# M3351 register map
File version: 1.0
Registers are 32-bit, read-write, reset 0x0 unless marked. A register's access mark holds for its fields unless they carry their own. Offsets are from the block's base; [hi:lo] are bit positions; lines under a group give offsets from that group; 'fields as' and 'values as' point back to an identical list.

## CLK (part 2 of 2) — CLK Register Map
Base 0x40000200
0x78 CLK_CDUPB — Clock Frequency Range Detector Upper Boundary Register
  [10:0] UPERBD — HXT Clock Frequency Range Detector Upper Boundary Value. The bits define the maximum value of frequency range detector window. When HXT frequency higher than this maximum frequency value, the HXT Clock Frequency Range Detector Interrupt Flag will set to 1.
0x7C CLK_CDLOWB — Clock Frequency Range Detector Lower Boundary Register
  [10:0] LOWERBD — HXT Clock Frequency Range Detector Lower Boundary Value. The bits define the minimum value of frequency range detector window. When HXT frequency lower than this minimum frequency value, the HXT Clock Frequency Range Detector Interrupt Flag will set to 1.
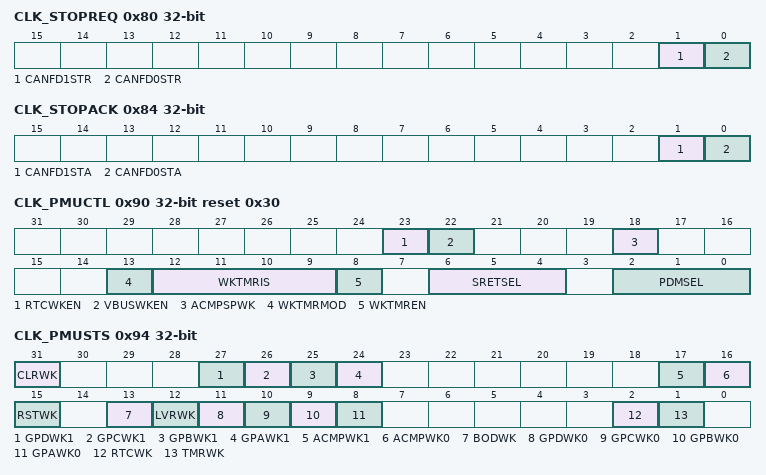
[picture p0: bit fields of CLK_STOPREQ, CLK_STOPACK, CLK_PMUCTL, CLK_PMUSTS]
0x80 CLK_STOPREQ — Clock Stop Request Register
  [1] CANFD1STR — CANFD1 Clock Stop Request. This bit is used to stop CANFD1 clock.
    0=CANFD1 clock is not stopped by this bit. (default); 1=Set this bit and check the CANFD1STA(CLK_STOPACK[1]) is 1, then CANFD1 clock stop
  [0] CANFD0STR — CANFD0 Clock Stop Request. This bit is used to stop CANFD0 clock.
    0=CANFD0 clock is not stopped by this bit. (default); 1=Set this bit and check the CANFD0STA(CLK_STOPACK[0]) is 1, then CANFD0 clock stop
0x84 CLK_STOPACK ro — Clock Stop Acknowledge Register
  [1] CANFD1STA — CANFD1 Clock Stop Acknowledge (Read Only). This bit is used to check CANFD1 clock stop by setting CANFD1STR(CLK_STOPREQ[1]).
    0=CANFD1 clock not stopped; 1=CANFD1 clock stopped
  [0] CANFD0STA — CANFD0 Clock Stop Acknowledge (Read Only). This bit is used to check CANFD0 clock stop by setting CANFD0STR(CLK_STOPREQ[0]).
    0=CANFD0 clock not stopped; 1=CANFD0 clock stopped
0x90 CLK_PMUCTL reset 0x30 — Power Manager Control Register
  [23] RTCWKEN — RTC Wake-up Enable Bit (Write Protect). Note: This bit is write protected. Refer to the SYS_REGLCTL register.
    0=RTC wake-up disabled at Standby Power-down mode; 1=RTC wake-up enabled at Standby Power-down mode
  [22] VBUSWKEN — VBUS Wake-up Enable Bit (Write Protect). Note: This bit is write protected. Refer to the SYS_REGLCTL register.
    0=VBUS transition wake-up disabled at Standby Power-down mode; 1=VBUS transition wake-up enabled at Standby Power-down mode
  [18] ACMPSPWK — ACMP Standby Power-down Mode Wake-up Enable Bit (Write Protect). Note 1: This bit is write protected. Refer to the SYS_REGLCTL register. Note 2: Set FILTSEL(ACMP_CTLx[15:13]) for comparator output filter count selection, the filter clock is LIRC/3 in ACMP SPD mode wakeup function.
    0=ACMP wake-up disabled at Standby Power-down mode; 1=ACMP wake-up enabled at Standby Power-down mode
  [13] WKTMRMOD — Wake-up Timer Mode (Write Protect). Note: This bit is write protected. Refer to the SYS_REGLCTL register.
    0=Wake-up timer started when entering Power-down mode; 1=Wake-up timer started immedially when WKTMREN (CLK_PMUCTL[8]) =1
  [12:9] WKTMRIS — Wake-up Timer Time-out Interval Select (Write Protect). These bits control wake-up timer time-out interval when chip at SPD mode. Note: These bits are write protected. Refer to the SYS_REGLCTL register.
    0=Time-out interval is 512 LIRC clocks (13.33ms); 1=Time-out interval is 1024 LIRC clocks (26.67ms); 2=Time-out interval is 2048 LIRC clocks (53.33ms); 3=Time-out interval is 4096 LIRC clocks (106.67ms); 4=Time-out interval is 8192 LIRC clocks (213.33ms); 5=Time-out interval is 16384 LIRC clocks (426.67ms); 6=Time-out interval is 32768 LIRC clocks (853.33ms); 7=Time-out interval is 65536 LIRC clocks (1706.67ms); 8=Time-out interval is 131072 LIRC clocks (3413.33ms); 9=Time-out interval is 262144 LIRC clocks (6826.67ms); 10=Time-out interval is 524288 LIRC clocks (13653.33ms); 11=Time-out interval is 1048576 LIRC clocks (27306.67ms); 12=Time-out interval is 2097152 LIRC clocks (54613.33ms); 13=Time-out interval is 4194304 LIRC clocks (109226.67ms)
  [8] WKTMREN — Wake-up Timer Enable Bit (Write Protect). Note: This bit is write protected. Refer to the SYS_REGLCTL register.
    0=Wake-up timer disabled at SPD mode; 1=Wake-up timer enabled at SPD mode
  [6:4] SRETSEL — SRAM Retention Range Select Bit (Write Protect). Select SRAM retention range when chip enter SPD mode. 1: SPD retention. 0: SPD no retention. Note: These bits are write protected. Refer to the SYS_REGLCTL register.
    0=No SRAM retention
  [2:0] PDMSEL — Power-down Mode Selection (Write Protect). These bits control chip power-down mode grade selection when CPU execute WFI/WFE instruction. Note: These bits are write protected. Refer to the SYS_REGLCTL register.
    0=Normal Power-down mode is selected (NPD1); 1=Low leakage Power-down mode is selected (NPD2); 2=Fast wake-up Power-down mode is selected (NPD0); 4=Standby Power-down mode is selected (SPD0); 5=Low leakage Standby Power-down mode is selected (SPD1)
0x94 CLK_PMUSTS — Power Manager Status Register
  [31] CLRWK — Clear Wake-up Flag. Note: This bit is auto cleared by hardware.
    0=No clear; 1=Clear all wake-up flag
  [27] GPDWK1 — GPD Wake-up 1 Flag (Read Only). This flag indicates that wake-up of chip from Standby Power-down mode was requested by a transition of selected one GPD group pins. Note: This flag needs to be cleared by setting CLRWK(CLK_PMUSTS[31] when entering SPD mode.
  [26] GPCWK1 — GPC Wake-up 1 Flag (Read Only). This flag indicates that wake-up of chip from Standby Power-down mode was requested by a transition of selected one GPC group pins. Note: This flag needs to be cleared by setting CLRWK(CLK_PMUSTS[31] when entering SPD mode.
  [25] GPBWK1 — GPB Wake-up 1 Flag (Read Only). This flag indicates that wake-up of chip from Standby Power-down mode was requested by a transition of selected one GPB group pins. Note: This flag needs to be cleared by setting CLRWK(CLK_PMUSTS[31] when entering SPD mode.
  [24] GPAWK1 — GPA Wake-up 1 Flag (Read Only). This flag indicates that wake-up of chip from Standby Power-down mode was requested by a transition of selected one GPA group pins. Note: This flag needs to be cleared by setting CLRWK(CLK_PMUSTS[31] when entering SPD mode.
  [17] ACMPWK1 — ACMP1 Wake-up Flag (Read Only). This flag indicates that wakeup of device from Standby Power-down mode (SPD) was requested with an ACMP1 transition. Note: This flag needs to be cleared by setting CLRWK(CLK_PMUSTS[31] when entering SPD mode.
  [16] ACMPWK0 — ACMP0 Wake-up Flag (Read Only). This flag indicates that wakeup of device from Standby Power-down mode (SPD) was requested with an ACMP0 transition. Note: This flag needs to be cleared by setting CLRWK(CLK_PMUSTS[31] when entering SPD mode.
  [15] RSTWK — RST pin Wake-up Flag (Read Only). This flag indicates that wakeup of device from Standby Power-down (SPD) mode was requested with a RST pin trigger happened. Note: This flag needs to be cleared by setting CLRWK(CLK_PMUSTS[31] when entering SPD mode.
  [13] BODWK — BOD Wake-up Flag (Read Only). This flag indicates that wakeup of device from Standby Power-down mode (SPD) was requested with a BOD happened. Note: This flag needs to be cleared by setting CLRWK(CLK_PMUSTS[31] when entering SPD mode.
  [12] LVRWK — LVR Wake-up Flag (Read Only). This flag indicates that wakeup of device from Standby Power-down mode was requested with a LVR happened. Note: This flag needs to be cleared by setting CLRWK(CLK_PMUSTS[31] when entering SPD mode.
  [11] GPDWK0 — GPD Wake-up 0 Flag (Read Only). This flag indicates that wake-up of chip from Standby Power-down mode was requested by a transition of selected one GPD group pins. Note: This flag needs to be cleared by setting CLRWK(CLK_PMUSTS[31] when entering SPD mode.
  [10] GPCWK0 — GPC Wake-up 0 Flag (Read Only). This flag indicates that wake-up of chip from Standby Power-down mode was requested by a transition of selected one GPC group pins. Note: This flag needs to be cleared by setting CLRWK(CLK_PMUSTS[31] when entering SPD mode.
  [9] GPBWK0 — GPB Wake-up 0 Flag (Read Only). This flag indicates that wake-up of chip from Standby Power-down mode was requested by a transition of selected one GPB group pins. Note: This flag needs to be cleared by setting CLRWK(CLK_PMUSTS[31] when entering SPD mode.
  [8] GPAWK0 — GPA Wake-up 0 Flag (Read Only). This flag indicates that wake-up of chip from Standby Power-down mode was requested by a transition of selected one GPA group pins. Note: This flag needs to be cleared by setting CLRWK(CLK_PMUSTS[31] when entering SPD mode.
  [2] RTCWK — RTC Wake-up Flag (Read Only). This flag indicates that wakeup of device from Standby Power-down (SPD) mode was requested with a RTC alarm, tick time or tamper happened. Note: This flag needs to be cleared by setting CLRWK(CLK_PMUSTS[31] when entering SPD mode.
  [1] TMRWK — Timer Wake-up Flag (Read Only). This flag indicates that wake-up of chip from Standby Power-down (SPD) mode was requested by wakeup timer time-out. Note: This flag needs to be cleared by setting CLRWK(CLK_PMUSTS[31] when entering SPD mode.
0x9C CLK_SWKDBCTL — GPIO Standby Power-down Wake-up De-bounce Control Register
  [3:0] SWKDBCLKSEL — Standby Power-down Wake-up De-bounce Sampling Cycle Selection. Note: De-bounce counter clock source is LIRC/3.
    0=Sample wake-up input once per 1 clock; 1=Sample wake-up input once per 2 clocks; 2=Sample wake-up input once per 4 clocks; 3=Sample wake-up input once per 8 clocks; 4=Sample wake-up input once per 16 clocks; 5=Sample wake-up input once per 32 clocks; 6=Sample wake-up input once per 64 clocks; 7=Sample wake-up input once per 128 clocks; 8=Sample wake-up input once per 256 clocks; 9=Sample wake-up input once per 2*256 clocks; 10=Sample wake-up input once per 4*256 clocks; 11=Sample wake-up input once per 8*256 clocks; 12=Sample wake-up input once per 16*256 clocks; 13=Sample wake-up input once per 32*256 clocks; 14=Sample wake-up input once per 64*256 clocks; 15=Sample wake-up input once per 128*256 clocks
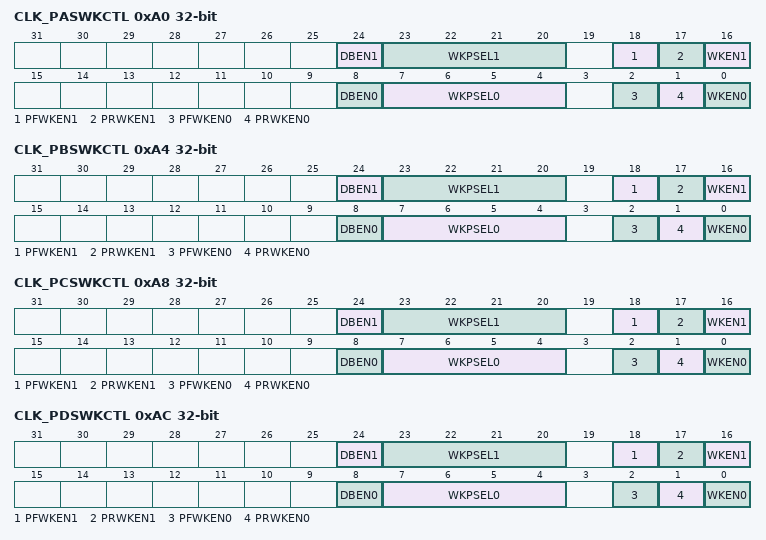
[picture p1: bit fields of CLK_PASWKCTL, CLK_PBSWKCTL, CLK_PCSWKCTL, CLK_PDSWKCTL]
0xA0 CLK_PASWKCTL — GPA Standby Power-down Wake-up Control Register
  [24] DBEN1 — GPA Pin 1 Input Signal De-bounce Enable Bit. The DBEN bit is used to enable the de-bounce function for each corresponding I/O. If the input signal pulse width cannot be sampled by continuous two de-bounce sample cycle, the input signal transition is seen as the signal bounce and will not trigger the wake-up. The de-bounce clock source is the 32 kHz internal low speed RC oscillator. The de-bounce function is valid only for edgetriggered.
    0=GPA group pin 1 Wakeup-I/O pin De-bounce function Disabled; 1=GPA group pin 1 Wakeup-I/O pin De-bounce function Enabled
  [23:20] WKPSEL1 — GPA Pin 1 Wakeup-I/O Pin Select
    0=GPA.0 as Wakeup-I/O function select; 1=GPA.1 as Wakeup-I/O function select; 2=GPA.2 as Wakeup-I/O function select; 3=GPA.3 as Wakeup-I/O function select; 4=GPA.4 as Wakeup-I/O function select; 5=GPA.5 as Wakeup-I/O function select; 6=GPA.6 as Wakeup-I/O function select; 7=GPA.7 as Wakeup-I/O function select; 8=GPA.8 as Wakeup-I/O function select; 9=GPA.9 as Wakeup-I/O function select; 10=GPA.10 as Wakeup-I/O function select; 11=GPA.11 as Wakeup-I/O function select; 12=GPA.12 as Wakeup-I/O function select; 13=GPA.13 as Wakeup-I/O function select; 14=GPA.14 as Wakeup-I/O function select; 15=GPA.15 as Wakeup-I/O function select
  [18] PFWKEN1 — GPA Pin 1 Falling Edge Detect Enable Bit
    0=GPA group pin 1 falling edge detect function Disabled; 1=GPA group pin 1 falling edge detect function Enabled
  [17] PRWKEN1 — GPA Pin 1 Rising Edge Detect Enable Bit
    0=GPA group pin 1 rising edge detect function Disabled; 1=GPA group pin 1 rising edge detect function Enabled
  [16] WKEN1 — GPA Pin 1 Wake-up Enable Bit
    0=GPA group pin 1 wake-up function Disabled; 1=GPA group pin 1 wake-up function Enabled
  [8] DBEN0 — GPA Pin 0 Input Signal De-bounce Enable Bit. The DBEN bit is used to enable the de-bounce function for each corresponding I/O. If the input signal pulse width cannot be sampled by continuous two de-bounce sample cycle, the input signal transition is seen as the signal bounce and will not trigger the wake-up. The de-bounce clock source is the 32 kHz internal low speed RC oscillator. The de-bounce function is valid only for edgetriggered.
    0=GPA group pin 0 Wake-up-I/O pin De-bounce function Disabled; 1=GPA group pin 0 Wakeup-I/O pin De-bounce function Enabled
  [7:4] WKPSEL0 — GPA Pin 0 Wakeup-I/O Pin Select
    0=GPA.0 as Wake-up-I/O function select; 1=GPA.1 as Wakeup-I/O function select; 2=GPA.2 as Wakeup-I/O function select; 3=GPA.3 as Wakeup-I/O function select; 4=GPA.4 as Wakeup-I/O function select; 5=GPA.5 as Wakeup-I/O function select; 6=GPA.6 as Wakeup-I/O function select; 7=GPA.7 as Wakeup-I/O function select; 8=GPA.8 as Wakeup-I/O function select; 9=GPA.9 as Wakeup-I/O function select; 10=GPA.10 as Wakeup-I/O function select; 11=GPA.11 as Wakeup-I/O function select; 12=GPA.12 as Wakeup-I/O function select; 13=GPA.13 as Wakeup-I/O function select; 14=GPA.14 as Wakeup-I/O function select; 15=GPA.15 as Wakeup-I/O function select
  [2] PFWKEN0 — GPA Pin 0 Falling Edge Detect Enable Bit
    0=GPA group pin 0 falling edge detect function Disabled; 1=GPA group pin 0 falling edge detect function Enabled
  [1] PRWKEN0 — GPA Pin 0 Rising Edge Detect Enable Bit
    0=GPA group pin 0 rising edge detect function Disabled; 1=GPA group pin 0 rising edge detect function Enabled
  [0] WKEN0 — GPA Pin 0 Wake-up-I/O Enable Bit
    0=GPA group pin 0 Wake-up-I/O function Disabled; 1=GPA group pin 0 Wakeup-I/O function Enabled
0xA4 CLK_PBSWKCTL — GPB Standby Power-down Wake-up Control Register
  [24] DBEN1 — GPB Pin 1 Input Signal De-bounce Enable Bit. The DBEN bit is used to enable the de-bounce function for each corresponding I/O. If the input signal pulse width cannot be sampled by continuous two de-bounce sample cycle, the input signal transition is seen as the signal bounce and will not trigger the wake-up. The de-bounce clock source is the 32 kHz internal low speed RC oscillator. The de-bounce function is valid only for edgetriggered.
    0=GPB group pin 1 Wakeup-I/O pin De-bounce function Disabled; 1=GPB group pin 1 Wakeup-I/O pin De-bounce function Enabled
  [23:20] WKPSEL1 — GPB Pin 1 Wakeup-I/O Pin Select
    0=GPB.0 as Wakeup-I/O function select; 1=GPB.1 as Wakeup-I/O function select; 2=GPB.2 as Wakeup-I/O function select; 3=GPB.3 as Wakeup-I/O function select; 4=GPB.4 as Wakeup-I/O function select; 5=GPB.5 as Wakeup-I/O function select; 6=GPB.6 as Wakeup-I/O function select; 7=GPB.7 as Wakeup-I/O function select; 8=GPB.8 as Wakeup-I/O function select; 9=GPB.9 as Wakeup-I/O function select; 10=GPB.10 as Wakeup-I/O function select; 11=GPB.11 as Wakeup-I/O function select; 12=GPB.12 as Wakeup-I/O function select; 13=GPB.13 as Wakeup-I/O function select; 14=GPB.14 as Wakeup-I/O function select; 15=GPB.15 as Wakeup-I/O function select
  [18] PFWKEN1 — GPB Pin 1 Falling Edge Detect Enable Bit
    0=GPB group pin 1 falling edge detect function Disabled; 1=GPB group pin 1 falling edge detect function Enabled
  [17] PRWKEN1 — GPB Pin 1 Rising Edge Detect Enable Bit
    0=GPB group pin 1 rising edge detect function Disabled; 1=GPB group pin 1 rising edge detect function Enabled
  [16] WKEN1 — GPB Pin 1 Wake-up Enable Bit
    0=GPB group pin 1 wake-up function Disabled; 1=GPB group pin 1 wake-up function Enabled
  [8] DBEN0 — GPB Pin 0 Input Signal De-bounce Enable Bit. The DBEN bit is used to enable the de-bounce function for each corresponding I/O. If the input signal pulse width cannot be sampled by continuous two de-bounce sample cycle, the input signal transition is seen as the signal bounce and will not trigger the wake-up. The de-bounce clock source is the 32 kHz internal low speed RC oscillator. The de-bounce function is valid only for edgetriggered.
    0=GPB group pin 0 Wakeup-I/O pin De-bounce function Disabled; 1=GPB group pin 0 Wakeup-I/O pin De-bounce function Enabled
  [7:4] WKPSEL0 — GPB Pin 0 Wakeup-I/O Pin Select
    values as WKPSEL1
  [2] PFWKEN0 — GPB Pin 0 Falling Edge Detect Enable Bit
    0=GPB group pin 0 falling edge detect function Disabled; 1=GPB group pin 0 falling edge detect function Enabled
  [1] PRWKEN0 — GPB Pin 0 Rising Edge Detect Enable Bit
    0=GPB group pin 0 rising edge detect function Disabled; 1=GPB group pin 0 rising edge detect function Enabled
  [0] WKEN0 — GPB Pin 0 Wakeup-I/O Enable Bit
    0=GPB group pin 0 Wakeup-I/O function Disabled; 1=GPB group pin 0 Wakeup-I/O function Enabled
0xA8 CLK_PCSWKCTL — GPC Standby Power-down Wake-up Control Register
  [24] DBEN1 — GPC Pin 1 Input Signal De-bounce Enable Bit. The DBEN bit is used to enable the de-bounce function for each corresponding I/O. If the input signal pulse width cannot be sampled by continuous two de-bounce sample cycle, the input signal transition is seen as the signal bounce and will not trigger the wake-up. The de-bounce clock source is the 32 kHz internal low speed RC oscillator. The de-bounce function is valid only for edgetriggered.
    0=GPC group pin 1 Wakeup-I/O pin De-bounce function Disabled; 1=GPC group pin 1 Wakeup-I/O pin De-bounce function Enabled
  [23:20] WKPSEL1 — GPC Pin 1 Wakeup-I/O Pin Select
    0=GPC.0 as Wakeup-I/O function select; 1=GPC.1 as Wakeup-I/O function select; 2=GPC.2 as Wakeup-I/O function select; 3=GPC.3 as Wakeup-I/O function select; 4=GPC.4 as Wakeup-I/O function select; 5=GPC.5 as Wakeup-I/O function select; 6=GPC.6 as Wakeup-I/O function select; 7=GPC.7 as Wakeup-I/O function select; 8=GPC.8 as Wakeup-I/O function select; 9=GPC.9 as Wakeup-I/O function select; 10=GPC.10 as Wakeup-I/O function select; 11=GPC.11 as Wakeup-I/O function select; 12=GPC.12 as Wakeup-I/O function select; 13=GPC.13 as Wakeup-I/O function select; 14=GPC.14 as Wakeup-I/O function select; 15=GPC.15 as Wakeup-I/O function select
  [18] PFWKEN1 — GPC Pin 1 Falling Edge Detect Enable Bit
    0=GPC group pin 1 falling edge detect function Disabled; 1=GPC group pin 1 falling edge detect function Enabled
  [17] PRWKEN1 — GPC Pin 1 Rising Edge Detect Enable Bit
    0=GPC group pin 1 rising edge detect function Disabled; 1=GPC group pin 1 rising edge detect function Enabled
  [16] WKEN1 — GPC Pin 1 Wake-up Enable Bit
    0=GPC group pin 1 wake-up function Disabled; 1=GPC group pin 1 wake-up function Enabled
  [8] DBEN0 — GPC Pin 0 Input Signal De-bounce Enable Bit. The DBEN bit is used to enable the de-bounce function for each corresponding I/O. If the input signal pulse width cannot be sampled by continuous two de-bounce sample cycle, the input signal transition is seen as the signal bounce and will not trigger the wake-up. The de-bounce clock source is the 32 kHz internal low speed RC oscillator. The de-bounce function is valid only for edgetriggered.
    0=GPC group pin 0 Wakeup-I/O pin De-bounce function Disabled; 1=GPC group pin 0 Wakeup-I/O pin De-bounce function Enabled
  [7:4] WKPSEL0 — GPC Pin 0 Wakeup-I/O Pin Select
    values as WKPSEL1
  [2] PFWKEN0 — GPC Pin 0 Falling Edge Detect Enable Bit
    0=GPC group pin 0 falling edge detect function Disabled; 1=GPC group pin 0 falling edge detect function Enabled
  [1] PRWKEN0 — GPC Pin 0 Rising Edge Detect Enable Bit
    0=GPC group pin 0 rising edge detect function Disabled; 1=GPC group pin 0 rising edge detect function Enabled
  [0] WKEN0 — GPC Pin 0 Wakeup-I/O Enable Bit
    0=GPC group pin 0 Wakeup-I/O function Disabled; 1=GPC group pin 0 Wakeup-I/O function Enabled
0xAC CLK_PDSWKCTL — GPD Standby Power-down Wake-up Control Register
  [24] DBEN1 — GPD Pin 1 Input Signal De-bounce Enable Bit. The DBEN bit is used to enable the de-bounce function for each corresponding I/O. If the input signal pulse width cannot be sampled by continuous two de-bounce sample cycle, the input signal transition is seen as the signal bounce and will not trigger the wake-up. The de-bounce clock source is the 32 kHz internal low speed RC oscillator. The de-bounce function is valid only for edgetriggered.
    0=GPD group pin 1 Wakeup-I/O pin De-bounce function Disabled; 1=GPD group pin 1 Wakeup-I/O pin De-bounce function Enabled
  [23:20] WKPSEL1 — GPD Pin 1 Wakeup-I/O Pin Select
    0=GPD.0 as Wakeup-I/O function select; 1=GPD.1 as Wakeup-I/O function select; 2=GPD.2 as Wakeup-I/O function select; 3=GPD.3 as Wakeup-I/O function select; 4=GPD.4 as Wakeup-I/O function select; 5=GPD.5 as Wakeup-I/O function select; 6=GPD.6 as Wakeup-I/O function select; 7=GPD.7 as Wakeup-I/O function select; 8=GPD.8 as Wakeup-I/O function select; 9=GPD.9 as Wakeup-I/O function select; 10=GPD.10 as Wakeup-I/O function select; 11=GPD.11 as Wakeup-I/O function select; 12=GPD.12 as Wakeup-I/O function select; 13=GPD.13 as Wakeup-I/O function select; 14=GPD.14 as Wakeup-I/O function select; 15=GPD.15 as Wakeup-I/O function select
  [18] PFWKEN1 — GPD Pin 1 Falling Edge Detect Enable Bit
    0=GPD group pin 1 falling edge detect function Disabled; 1=GPD group pin 1 falling edge detect function Enabled
  [17] PRWKEN1 — GPD Pin 1 Rising Edge Detect Enable Bit
    0=GPD group pin 1 rising edge detect function Disabled; 1=GPD group pin 1 rising edge detect function Enabled
  [16] WKEN1 — GPD Pin 1 Wake-up Enable Bit
    0=GPD group pin 1 wake-up function Disabled; 1=GPD group pin 1 wake-up function Enabled
  [8] DBEN0 — GPD Pin 0 Input Signal De-bounce Enable Bit. The DBEN bit is used to enable the de-bounce function for each corresponding I/O. If the input signal pulse width cannot be sampled by continuous two de-bounce sample cycle, the input signal transition is seen as the signal bounce and will not trigger the wake-up. The de-bounce clock source is the 32 kHz internal low speed RC oscillator. The de-bounce function is valid only for edgetriggered.
    0=GPD group pin 0 Wakeup-I/O pin De-bounce function Disabled; 1=GPD group pin 0 Wakeup-I/O pin De-bounce function Enabled
  [7:4] WKPSEL0 — GPD Pin 0 Wakeup-I/O Pin Select
    values as WKPSEL1
  [2] PFWKEN0 — GPD Pin 0 Falling Edge Detect Enable Bit
    0=GPD group pin 0 falling edge detect function Disabled; 1=GPD group pin 0 falling edge detect function Enabled
  [1] PRWKEN0 — GPD Pin 0 Rising Edge Detect Enable Bit
    0=GPD group pin 0 rising edge detect function Disabled; 1=GPD group pin 0 rising edge detect function Enabled
  [0] WKEN0 — GPD Pin 0 Wakeup-I/O Enable Bit
    0=GPD group pin 0 Wakeup-I/O function Disabled; 1=GPD group pin 0 Wakeup-I/O function Enabled
0xB0 CLK_IOPDCTL — GPIO Standby Power-down Control Register
  [0] IOHR — GPIO Hold Release. When GPIO enters standby power-down mode, all I/O status will turn to input floating status. After chip is woken up from standby power-down mode, the I/O are still keep input floating status until user set this bit to release I/O hold status. Note: This bit is auto cleared by hardware.
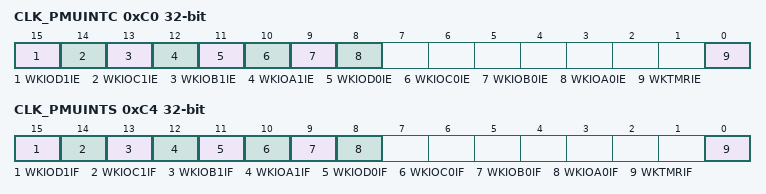
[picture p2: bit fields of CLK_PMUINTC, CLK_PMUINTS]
0xC0 CLK_PMUINTC — Power Manager Interrupt Control Register
  [15] WKIOD1IE — Wakeup-I/O GPD group Pin 1 Interrupt Enable Bit
    0=Wakeup-I/O interrupt function Disabled; 1=Wakeup-I/O interrupt function Enabled
  [14] WKIOC1IE — Wakeup-I/O GPC group Pin 1 Interrupt Enable Bit
    values as WKIOD1IE
  [13] WKIOB1IE — Wakeup-I/O GPB group Pin 1 Interrupt Enable Bit
    values as WKIOD1IE
  [12] WKIOA1IE — Wakeup-I/O GPA group Pin 1 Interrupt Enable Bit
    values as WKIOD1IE
  [11] WKIOD0IE — Wakeup-I/O GPD group Pin 0 Interrupt Enable Bit
    values as WKIOD1IE
  [10] WKIOC0IE — Wakeup-I/O GPC group Pin 0 Interrupt Enable Bit
    values as WKIOD1IE
  [9] WKIOB0IE — Wakeup-I/O GPB group Pin 0 Interrupt Enable Bit
    values as WKIOD1IE
  [8] WKIOA0IE — Wakeup-I/O GPA group Pin 0 Interrupt Enable Bit
    values as WKIOD1IE
  [0] WKTMRIE — Wakeup-Timer Interrupt Enable Bit
    0=Wakeup-Timer interrupt function Disabled; 1=Wakeup-Timer interrupt function Enabled
0xC4 CLK_PMUINTS — Power Manager Interrupt Status Register
  [15] WKIOD1IF — Wakeup-I/O GPD group Pin 1 Interrupt Flag. This flag indicates that Wakeup-I/O interrupt happened. Note: Software can clear this bit by writing 1 to it.
  [14] WKIOC1IF — Wakeup-I/O GPC group Pin 1 Interrupt Flag. This flag indicates that Wakeup-I/O interrupt happened. Note: Software can clear this bit by writing 1 to it.
  [13] WKIOB1IF — Wakeup-I/O GPB group Pin 1 Interrupt Flag. This flag indicates that Wakeup-I/O interrupt happened. Note: Software can clear this bit by writing 1 to it.
  [12] WKIOA1IF — Wakeup-I/O GPA group Pin 1 Interrupt Flag. This flag indicates that Wakeup-I/O interrupt happened. Note: Software can clear this bit by writing 1 to it.
  [11] WKIOD0IF — Wakeup-I/O GPD group Pin 0 Interrupt Flag. This flag indicates that Wakeup-I/O interrupt happened. Note: Software can clear this bit by writing 1 to it.
  [10] WKIOC0IF — Wakeup-I/O GPC group Pin 0 Interrupt Flag. This flag indicates that Wakeup-I/O interrupt happened. Note: Software can clear this bit by writing 1 to it.
  [9] WKIOB0IF — Wakeup-I/O GPB group Pin 0 Interrupt Flag. This flag indicates that Wakeup-I/O interrupt happened. Note: Software can clear this bit by writing 1 to it.
  [8] WKIOA0IF — Wakeup-I/O GPA group Pin 0 Interrupt Flag. This flag indicates that Wakeup-I/O interrupt happened. Note: Software can clear this bit by writing 1 to it.
  [0] WKTMRIF — Wakeup-Timer Interrupt Flag. This flag indicates that Wakeup-Timer interrupt happened. Note: Software can clear this bit by writing 1 to it.
